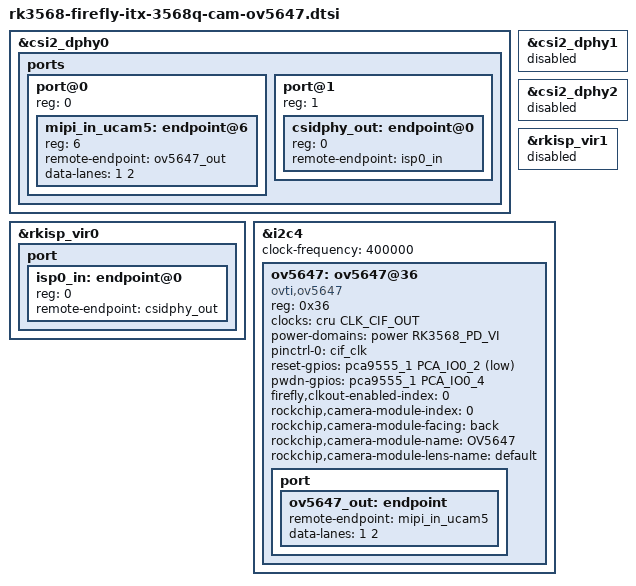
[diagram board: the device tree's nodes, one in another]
// SPDX-License-Identifier: (GPL-2.0+ OR MIT)
/*
 * Copyright (c) 2024 Rockchip Electronics Co., Ltd.
 */

&csi2_dphy0 {
	status = "okay";

	ports {
		#address-cells = <1>;
		#size-cells = <0>;
		port@0 {
			reg = <0>;
			#address-cells = <1>;
			#size-cells = <0>;

			mipi_in_ucam5: endpoint@6 {  // Adjust the @6 and mipi_in_ucam5 labels as needed
				reg = <6>;
				remote-endpoint = <&ov5647_out>;  // Reference to the OV5647 output
				data-lanes = <1 2>;  // OV5647 typically uses 2 data lanes
			};
		};
		port@1 {
			reg = <1>;
			#address-cells = <1>;
			#size-cells = <0>;

			csidphy_out: endpoint@0 {
				reg = <0>;
				remote-endpoint = <&isp0_in>;
			};
		};
	};
};

&csi2_dphy1 {
	status = "disabled";
};

&csi2_dphy2 {
	status = "disabled";
};

&rkisp_vir0 {
	status = "okay";

	port {
		#address-cells = <1>;
		#size-cells = <0>;

		isp0_in: endpoint@0 {
			reg = <0>;
			remote-endpoint = <&csidphy_out>;
		};
	};
};

&rkisp_vir1 {
	status = "disabled";
};

&i2c4 {
	status = "okay";
	clock-frequency = <400000>;

	ov5647: ov5647@36 {  // OV5647 typically has an I2C address of 0x36
        status = "okay";
        compatible = "ovti,ov5647";
        reg = <0x36>;
        clocks = <&cru CLK_CIF_OUT>;
        clock-names = "xvclk";
        power-domains = <&power RK3568_PD_VI>;
        pinctrl-names = "default";
        pinctrl-0 = <&cif_clk>;

        reset-gpios = <&pca9555_1 PCA_IO0_2 GPIO_ACTIVE_LOW>;  // Adjust based on your setup
        pwdn-gpios = <&pca9555_1 PCA_IO0_4 GPIO_ACTIVE_HIGH>;

        firefly,clkout-enabled-index = <0>;
        rockchip,camera-module-index = <0>;
        rockchip,camera-module-facing = "back";
        rockchip,camera-module-name = "OV5647";
        rockchip,camera-module-lens-name = "default";

        port {
			ov5647_out: endpoint {
				remote-endpoint = <&mipi_in_ucam5>;  // Reference to the input port above
                data-lanes = <1 2>;  // Ensure this matches the lanes used by the OV5647
            };
        };
    };
};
